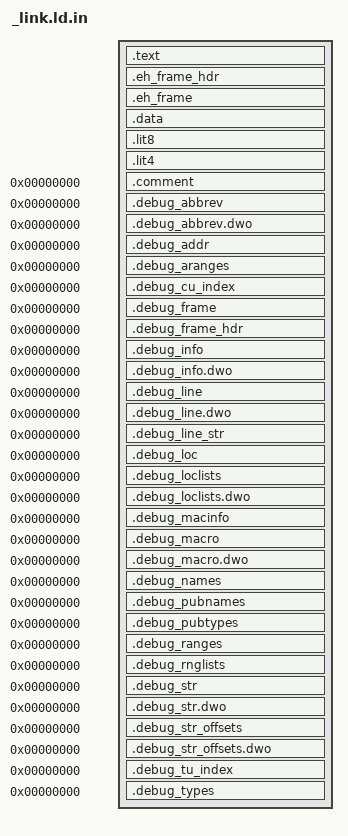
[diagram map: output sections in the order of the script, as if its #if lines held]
/*
 * MIPS32 linker script
 *
 *  kernel text
 *  kernel data
 *
 */

#undef mips
#define mips mips

#if defined(MACHINE_msim)
#define KERNEL_LOAD_ADDRESS 0x80100000
#endif

#if defined(MACHINE_lmalta) || defined(MACHINE_bmalta)
#define KERNEL_LOAD_ADDRESS 0x80200000
#endif

OUTPUT_ARCH(mips)
ENTRY(kernel_image_start)

SECTIONS {
	. = KERNEL_LOAD_ADDRESS;
	kernel_load_address = .;
	. = . + SIZEOF_HEADERS;

	.text : {
		ktext_start = .;
		/* FIXME: for some reason, mixing .text with .text.* produces a crash on malta-be */
		*(.text);
		*(.text.*);
		ktext_end = .;
	}

	/* stack unwinding data */
	.eh_frame_hdr : {
		eh_frame_hdr_start = .;
		*(.eh_frame_hdr) *(.eh_frame_entry .eh_frame_entry.*);
		eh_frame_hdr_end = .;
	}

	.eh_frame : {
		eh_frame_start = .;
		KEEP(*(.eh_frame .eh_frame.*));
		eh_frame_end = .;
	}

	.data : {
		kdata_start = .;
		*(.data .data.*);                       /* initialized data */
		*(.rodata .rodata.*);
		*(.sdata .sdata.*);
		*(.reginfo);
		*(.sbss .sbss.*);
		*(.scommon .scommon.*);
		*(.bss .bss.*);                        /* uninitialized static variables */
		*(COMMON);                      /* global variables */
	}

	_gp = . + 0x8000;
	.lit8 : { *(.lit8) }
	.lit4 : { *(.lit4) }

	kdata_end = .;

	.comment 0 : { *(.comment); }
	.debug_abbrev 0 : { *(.debug_abbrev); }
	.debug_abbrev.dwo 0 : { *(	.debug_abbrev.dwo); }
	.debug_addr 0 : { *(.debug_addr); }
	.debug_aranges 0 : { *(.debug_aranges); }
	.debug_cu_index 0 : { *(.debug_cu_index); }
	.debug_frame 0 : { *(.debug_frame); }
	.debug_frame_hdr 0 : { *(.debug_frame_hdr); }
	.debug_info 0 : { *(.debug_info); }
	.debug_info.dwo 0 : { *(.debug_info.dwo); }
	.debug_line 0 : { *(.debug_line); }
	.debug_line.dwo 0 : { *(.debug_line.dwo); }
	.debug_line_str 0 : { *(.debug_line_str); }
	.debug_loc 0 : { *(.debug_loc); }
	.debug_loclists 0 : { *(.debug_loclists); }
	.debug_loclists.dwo 0 : { *(.debug_loclists.dwo); }
	.debug_macinfo 0 : { *(.debug_macinfo); }
	.debug_macro 0 : { *(.debug_macro); }
	.debug_macro.dwo 0 : { *(.debug_macro.dwo); }
	.debug_names 0 : { *(.debug_names); }
	.debug_pubnames 0 : { *(.debug_pubnames); }
	.debug_pubtypes 0 : { *(.debug_pubtypes); }
	.debug_ranges 0 : { *(.debug_ranges); }
	.debug_rnglists 0 : { *(.debug_rnglists); }
	.debug_str 0 : { *(.debug_str); }
	.debug_str.dwo 0 : { *(.debug_str.dwo); }
	.debug_str_offsets 0 : { *(.debug_str_offsets); }
	.debug_str_offsets.dwo 0 : { *(.debug_str_offsets.dwo); }
	.debug_tu_index 0 : { *(.debug_tu_index); }
	.debug_types 0 : { *(.debug_types); }

	/DISCARD/ : {
		*(.mdebug*);
		*(.pdr);
		*(.comment);
		*(.note);
	}
}
